# ATSAML21G16B device description
Architecture: CORTEX-M0PLUS; Family: SAML; Series: SAML21
Registers are 32-bit, read-write, reset 0x0 unless marked. A register's access mark holds for its fields unless they carry their own. Offsets are from the block's base; [hi:lo] are bit positions; {n}, {i} and the like mark numbered series; 'fields as' and 'values as' point back to an identical list.

## OSC32KCTRL — 32k Oscillators Control
Instances: OSC32KCTRL 0x40001000
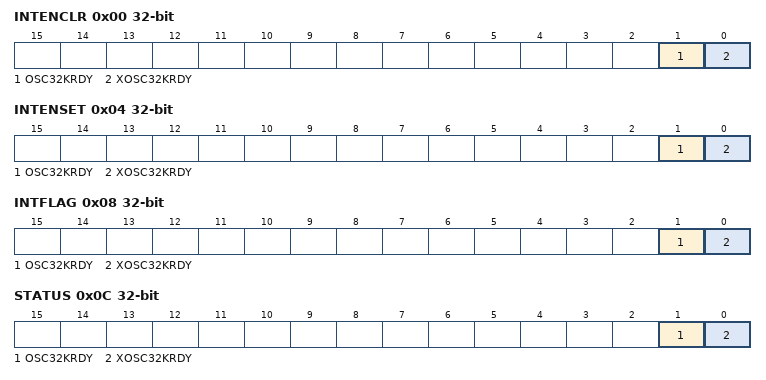
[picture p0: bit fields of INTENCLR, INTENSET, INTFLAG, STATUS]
0x00 INTENCLR (atomic clear) — Interrupt Enable Clear
  [1] OSC32KRDY — OSC32K Ready Interrupt Enable
  [0] XOSC32KRDY — XOSC32K Ready Interrupt Enable
0x04 INTENSET (atomic set) — Interrupt Enable Set
  fields as INTENCLR
0x08 INTFLAG (atomic clear) — Interrupt Flag Status and Clear
  [1] OSC32KRDY — OSC32K Ready
  [0] XOSC32KRDY — XOSC32K Ready
0x0C STATUS ro — Power and Clocks Status
  [1] OSC32KRDY — OSC32K Ready
  [0] XOSC32KRDY — XOSC32K Ready
0x10 RTCCTRL — Clock selection
  [2:0] RTCSEL — RTC Clock Selection
    0=ULP1K (1.024kHz from 32kHz internal ULP oscillator); 1=ULP32K (32.768kHz from 32kHz internal ULP oscillator); 2=OSC1K (1.024kHz from 32.768kHz internal oscillator); 3=OSC32K (32.768kHz from 32.768kHz internal oscillator); 4=XOSC1K (1.024kHz from 32.768kHz internal oscillator); 5=XOSC32K (32.768kHz from 32.768kHz external crystal oscillator)
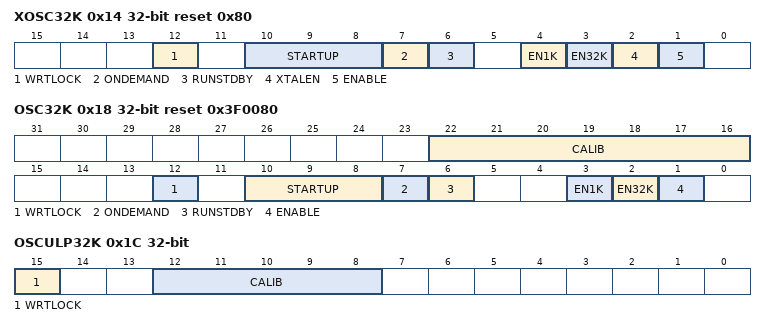
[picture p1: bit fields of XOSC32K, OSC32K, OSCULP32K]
0x14 XOSC32K reset 0x80 — 32kHz External Crystal Oscillator (XOSC32K) Control
  [12] WRTLOCK — Write Lock
  [10:8] STARTUP — Oscillator Start-Up Time
    0=CYCLE1 (0.122 ms); 1=CYCLE32 (1.068 ms); 2=CYCLE2048 (62.6 ms); 3=CYCLE4096 (125 ms); 4=CYCLE16384 (500 ms); 5=CYCLE32768 (1000 ms); 6=CYCLE65536 (2000 ms); 7=CYCLE131072 (4000 ms)
  [7] ONDEMAND — On Demand Control
  [6] RUNSTDBY — Run in Standby
  [4] EN1K — 1kHz Output Enable
  [3] EN32K — 32kHz Output Enable
  [2] XTALEN — Crystal Oscillator Enable
  [1] ENABLE — Oscillator Enable
0x18 OSC32K reset 0x3F0080 — 32kHz Internal Oscillator (OSC32K) Control
  [22:16] CALIB — Oscillator Calibration
  [12] WRTLOCK — Write Lock
  [10:8] STARTUP — Oscillator Start-Up Time
    0=CYCLE3 (0.092 ms); 1=CYCLE4 (0.122 ms); 2=CYCLE6 (0.183 ms); 3=CYCLE10 (0.305 ms); 4=CYCLE18 (0.549 ms); 5=CYCLE34 (1.038 ms); 6=CYCLE66 (2.014 ms); 7=CYCLE130 (3.967 ms)
  [7] ONDEMAND — On Demand Control
  [6] RUNSTDBY — Run in Standby
  [3] EN1K — 1kHz Output Enable
  [2] EN32K — 32kHz Output Enable
  [1] ENABLE — Oscillator Enable
0x1C OSCULP32K reset not defined — 32kHz Ultra Low Power Internal Oscillator (OSCULP32K) Control
  [15] WRTLOCK — Write Lock
  [12:8] CALIB — Oscillator Calibration

## PAC — Peripheral Access Controller
Instances: PAC 0x44000000
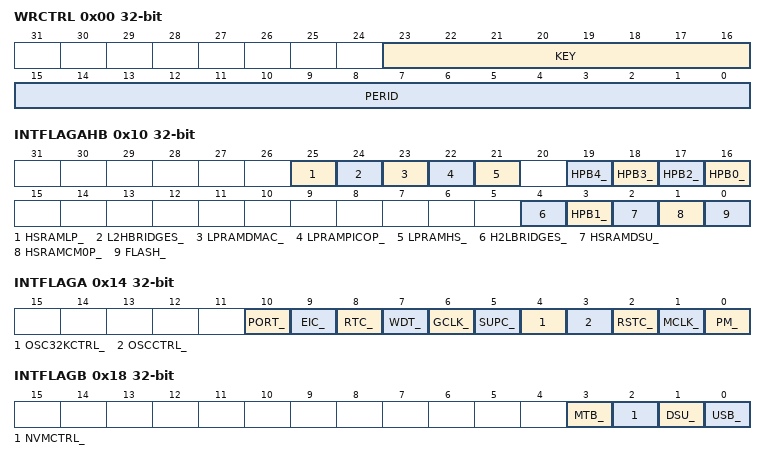
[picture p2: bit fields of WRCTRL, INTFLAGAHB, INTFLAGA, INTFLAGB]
0x00 WRCTRL — Write control
  [23:16] KEY — Peripheral access control key
    0=OFF (No action); 1=CLR (Clear protection); 2=SET (Set protection); 3=SETLCK (Set and lock protection)
  [15:0] PERID — Peripheral identifier
0x04 EVCTRL 8-bit — Event control
  [0] ERREO — Peripheral acess error event output
0x08 INTENCLR 8-bit (atomic clear) — Interrupt enable clear
  [0] ERR — Peripheral access error interrupt disable
0x09 INTENSET 8-bit (atomic set) — Interrupt enable set
  [0] ERR — Peripheral access error interrupt enable
0x10 INTFLAGAHB (atomic clear) — Bridge interrupt flag status
  [25] HSRAMLP_, [24] L2HBRIDGES_, [23] LPRAMDMAC_, [22] LPRAMPICOP_, [21] LPRAMHS_, [19] HPB4_, [18] HPB3_, [17] HPB2_, [16] HPB0_, [4] H2LBRIDGES_, [3] HPB1_, [2] HSRAMDSU_, [1] HSRAMCM0P_, [0] FLASH_
0x14 INTFLAGA (atomic clear) — Peripheral interrupt flag status - Bridge A
  [10] PORT_, [9] EIC_, [8] RTC_, [7] WDT_, [6] GCLK_, [5] SUPC_, [4] OSC32KCTRL_, [3] OSCCTRL_, [2] RSTC_, [1] MCLK_, [0] PM_
0x18 INTFLAGB (atomic clear) — Peripheral interrupt flag status - Bridge B
  [3] MTB_, [2] NVMCTRL_, [1] DSU_, [0] USB_
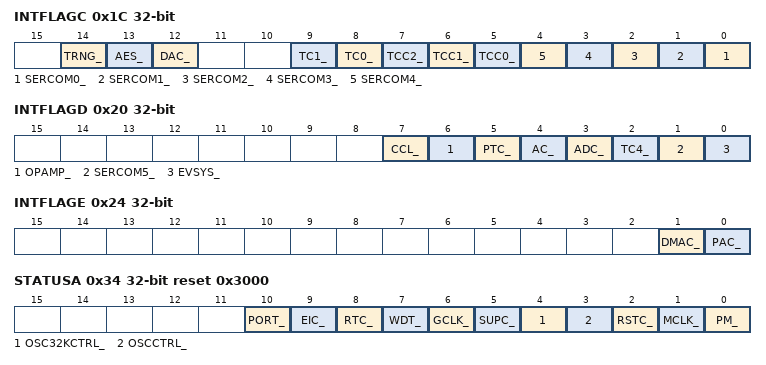
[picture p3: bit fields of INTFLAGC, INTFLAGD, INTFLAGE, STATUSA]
0x1C INTFLAGC (atomic clear) — Peripheral interrupt flag status - Bridge C
  [14] TRNG_, [13] AES_, [12] DAC_, [9] TC1_, [8] TC0_, [7] TCC2_, [6] TCC1_, [5] TCC0_, [n] SERCOM{n}_ (n=0..4)
0x20 INTFLAGD (atomic clear) — Peripheral interrupt flag status - Bridge D
  [7] CCL_, [6] OPAMP_, [5] PTC_, [4] AC_, [3] ADC_, [2] TC4_, [1] SERCOM5_, [0] EVSYS_
0x24 INTFLAGE (atomic clear) — Peripheral interrupt flag status - Bridge E
  [1] DMAC_, [0] PAC_
0x34 STATUSA ro reset 0x3000 — Peripheral write protection status - Bridge A
  [10] PORT_ — PORT APB Protect Enable
  [9] EIC_ — EIC APB Protect Enable
  [8] RTC_ — RTC APB Protect Enable
  [7] WDT_ — WDT APB Protect Enable
  [6] GCLK_ — GCLK APB Protect Enable
  [5] SUPC_ — SUPC APB Protect Enable
  [4] OSC32KCTRL_ — OSC32KCTRL APB Protect Enable
  [3] OSCCTRL_ — OSCCTRL APB Protect Enable
  [2] RSTC_ — RSTC APB Protect Enable
  [1] MCLK_ — MCLK APB Protect Enable
  [0] PM_ — PM APB Protect Enable
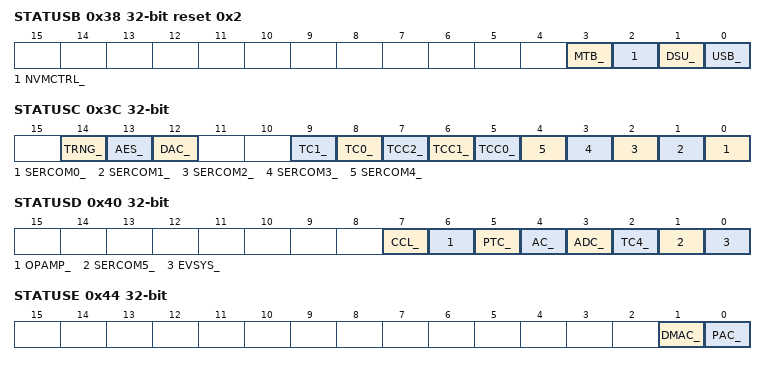
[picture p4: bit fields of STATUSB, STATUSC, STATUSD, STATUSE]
0x38 STATUSB ro reset 0x2 — Peripheral write protection status - Bridge B
  [3] MTB_ — MTB APB Protect Enable
  [2] NVMCTRL_ — NVMCTRL APB Protect Enable
  [1] DSU_ — DSU APB Protect Enable
  [0] USB_ — USB APB Protect Enable
0x3C STATUSC ro — Peripheral write protection status - Bridge C
  [14] TRNG_ — TRNG APB Protect Enable
  [13] AES_ — AES APB Protect Enable
  [12] DAC_ — DAC APB Protect Enable
  [9] TC1_ — TC1 APB Protect Enable
  [8] TC0_ — TC0 APB Protect Enable
  [7] TCC2_ — TCC2 APB Protect Enable
  [6] TCC1_ — TCC1 APB Protect Enable
  [5] TCC0_ — TCC0 APB Protect Enable
  [n] SERCOM{n}_ (n=0..4) — SERCOM{n} APB Protect Enable
0x40 STATUSD ro — Peripheral write protection status - Bridge D
  [7] CCL_ — CCL APB Protect Enable
  [6] OPAMP_ — OPAMP APB Protect Enable
  [5] PTC_ — PTC APB Protect Enable
  [4] AC_ — AC APB Protect Enable
  [3] ADC_ — ADC APB Protect Enable
  [2] TC4_ — TC4 APB Protect Enable
  [1] SERCOM5_ — SERCOM5 APB Protect Enable
  [0] EVSYS_ — EVSYS APB Protect Enable
0x44 STATUSE ro — Peripheral write protection status - Bridge E
  [1] DMAC_ — DMAC APB Protect Enable
  [0] PAC_ — PAC APB Protect Enable

## Notices in the file
Copyright (c) 2018 Microchip Technology Inc.
SPDX-License-Identifier: Apache-2.0
Licensed under the Apache License, Version 2.0 (the "License");
you may not use this file except in compliance with the License.
You may obtain a copy of the License at
http://www.apache.org/licenses/LICENSE-2.0
Unless required by applicable law or agreed to in writing, software
distributed under the License is distributed on an "AS IS" BASIS,
WITHOUT WARRANTIES OR CONDITIONS OF ANY KIND, either express or implied.
See the License for the specific language governing permissions and
limitations under the License.
